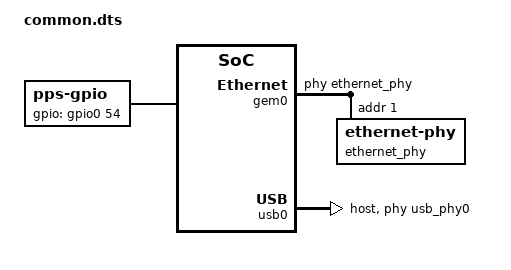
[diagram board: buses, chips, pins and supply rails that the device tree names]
/ {
  usb_phy0: phy0 {
    #phy-cells = <0>;
    compatible = "ulpi-phy";
    reg = <0xe0002000 0x1000>;
    view-port = <0x0170>;
    drv-vbus;
  };
  pps {
    compatible = "pps-gpio";
    gpios = <&gpio0 54 0>;
    capture-clear;
  };
};

&gem0 {
  phy-handle = <&ethernet_phy>;
  ethernet_phy: ethernet-phy@1 {
    reg = <1>;
  };
};

&usb0 {
  dr_mode = "host";
  usb-phy = <&usb_phy0>;
  xlnx,phy-reset-gpio = <&gpio0 46 0>;
};
